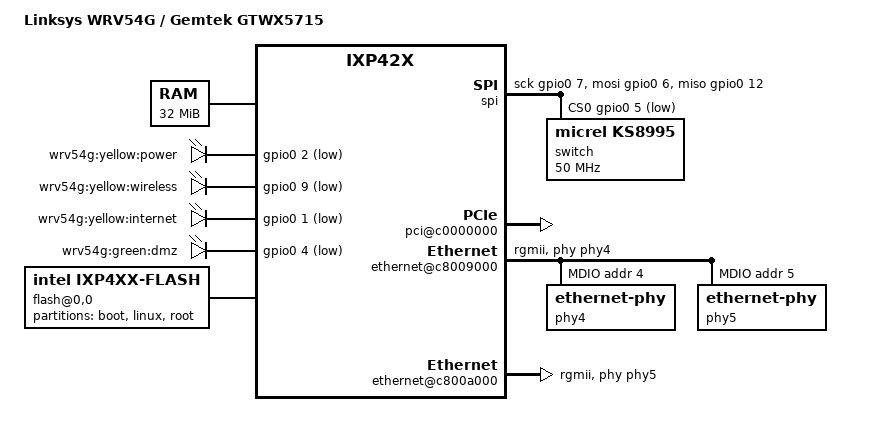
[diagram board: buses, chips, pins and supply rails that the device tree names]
/dts-v1/;
#include "intel-ixp42x.dtsi"
#include <dt-bindings/input/input.h>
/ {
	model = "Linksys WRV54G / Gemtek GTWX5715";
	compatible = "linksys,wrv54g", "gemtek,gtwx5715", "intel,ixp42x";
	#address-cells = <1>;
	#size-cells = <1>;
	memory@0 {
		device_type = "memory";
		reg = <0x00000000 0x2000000>;
	};
	chosen {
		bootargs = "console=ttyS0,115200n8";
		stdout-path = "uart1:115200n8";
	};
	aliases {
		serial0 = &uart1;
		serial1 = &uart0;
	};
	leds {
		compatible = "gpio-leds";
		led-power {
			label = "wrv54g:yellow:power";
			gpios = <&gpio0 2 GPIO_ACTIVE_LOW>;
			default-state = "on";
			linux,default-trigger = "heartbeat";
		};
		led-wireless {
			label = "wrv54g:yellow:wireless";
			gpios = <&gpio0 9 GPIO_ACTIVE_LOW>;
			default-state = "on";
		};
		led-internet {
			label = "wrv54g:yellow:internet";
			gpios = <&gpio0 1 GPIO_ACTIVE_LOW>;
			default-state = "on";
		};
		led-dmz {
			label = "wrv54g:green:dmz";
			gpios = <&gpio0 4 GPIO_ACTIVE_LOW>;
			default-state = "on";
		};
	};
	spi {
		compatible = "spi-gpio";
		#address-cells = <1>;
		#size-cells = <0>;
		sck-gpios = <&gpio0 7 GPIO_ACTIVE_HIGH>;
		miso-gpios = <&gpio0 12 GPIO_ACTIVE_HIGH>;
		mosi-gpios = <&gpio0 6 GPIO_ACTIVE_HIGH>;
		cs-gpios = <&gpio0 5 GPIO_ACTIVE_LOW>;
		num-chipselects = <1>;
		switch@0 {
			compatible = "micrel,ks8995";
			reg = <0>;
			spi-max-frequency = <50000000>;
		};
	};
	soc {
		bus@c4000000 {
			flash@0,0 {
				compatible = "intel,ixp4xx-flash", "cfi-flash";
				bank-width = <2>;
				intel,ixp4xx-eb-write-enable = <1>;
				reg = <0 0x00000000 0x00800000>;
				partitions {
					compatible = "fixed-partitions";
					#address-cells = <1>;
					#size-cells = <1>;
					partition@0 {
						label = "boot";
						reg = <0x0 0x140000>;
						read-only;
					};
					partition@140000 {
						label = "linux";
						reg = <0x140000 0x100000>;
						read-only;
					};
					partition@240000 {
						label = "root";
						reg = <0x240000 0x480000>;
						read-write;
					};
				};
			};
		};
		pci@c0000000 {
			status = "okay";
			#interrupt-cells = <1>;
			interrupt-map-mask = <0xf800 0 0 7>;
			interrupt-map =
			<0x0000 0 0 1 &gpio0 10 IRQ_TYPE_LEVEL_LOW>,  
			<0x0000 0 0 2 &gpio0 11 IRQ_TYPE_LEVEL_LOW>,  
			<0x0800 0 0 1 &gpio0 11 IRQ_TYPE_LEVEL_LOW>,  
			<0x0800 0 0 2 &gpio0 10 IRQ_TYPE_LEVEL_LOW>;  
		};
		ethernet@c8009000 {
			status = "okay";
			queue-rx = <&qmgr 3>;
			queue-txready = <&qmgr 20>;
			phy-mode = "rgmii";
			phy-handle = <&phy4>;
			mdio {
				#address-cells = <1>;
				#size-cells = <0>;
				phy4: ethernet-phy@4 {
					reg = <4>;
				};
				phy5: ethernet-phy@5 {
					reg = <5>;
				};
			};
		};
		ethernet@c800a000 {
			status = "okay";
			queue-rx = <&qmgr 4>;
			queue-txready = <&qmgr 21>;
			phy-mode = "rgmii";
			phy-handle = <&phy5>;
		};
	};
};
